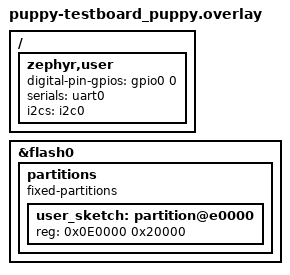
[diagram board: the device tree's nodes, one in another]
/ {
	zephyr,user {
		digital-pin-gpios = <&gpio0 0 0>;
		serials = <&uart0>;
		i2cs = <&i2c0>;
	};
};

&flash0 {
	partitions {
		compatible = "fixed-partitions";
		#address-cells = <1>;
		#size-cells = <1>;

		user_sketch: partition@e0000 {
			reg = <0x0E0000 0x20000>;
		};
	};
};
